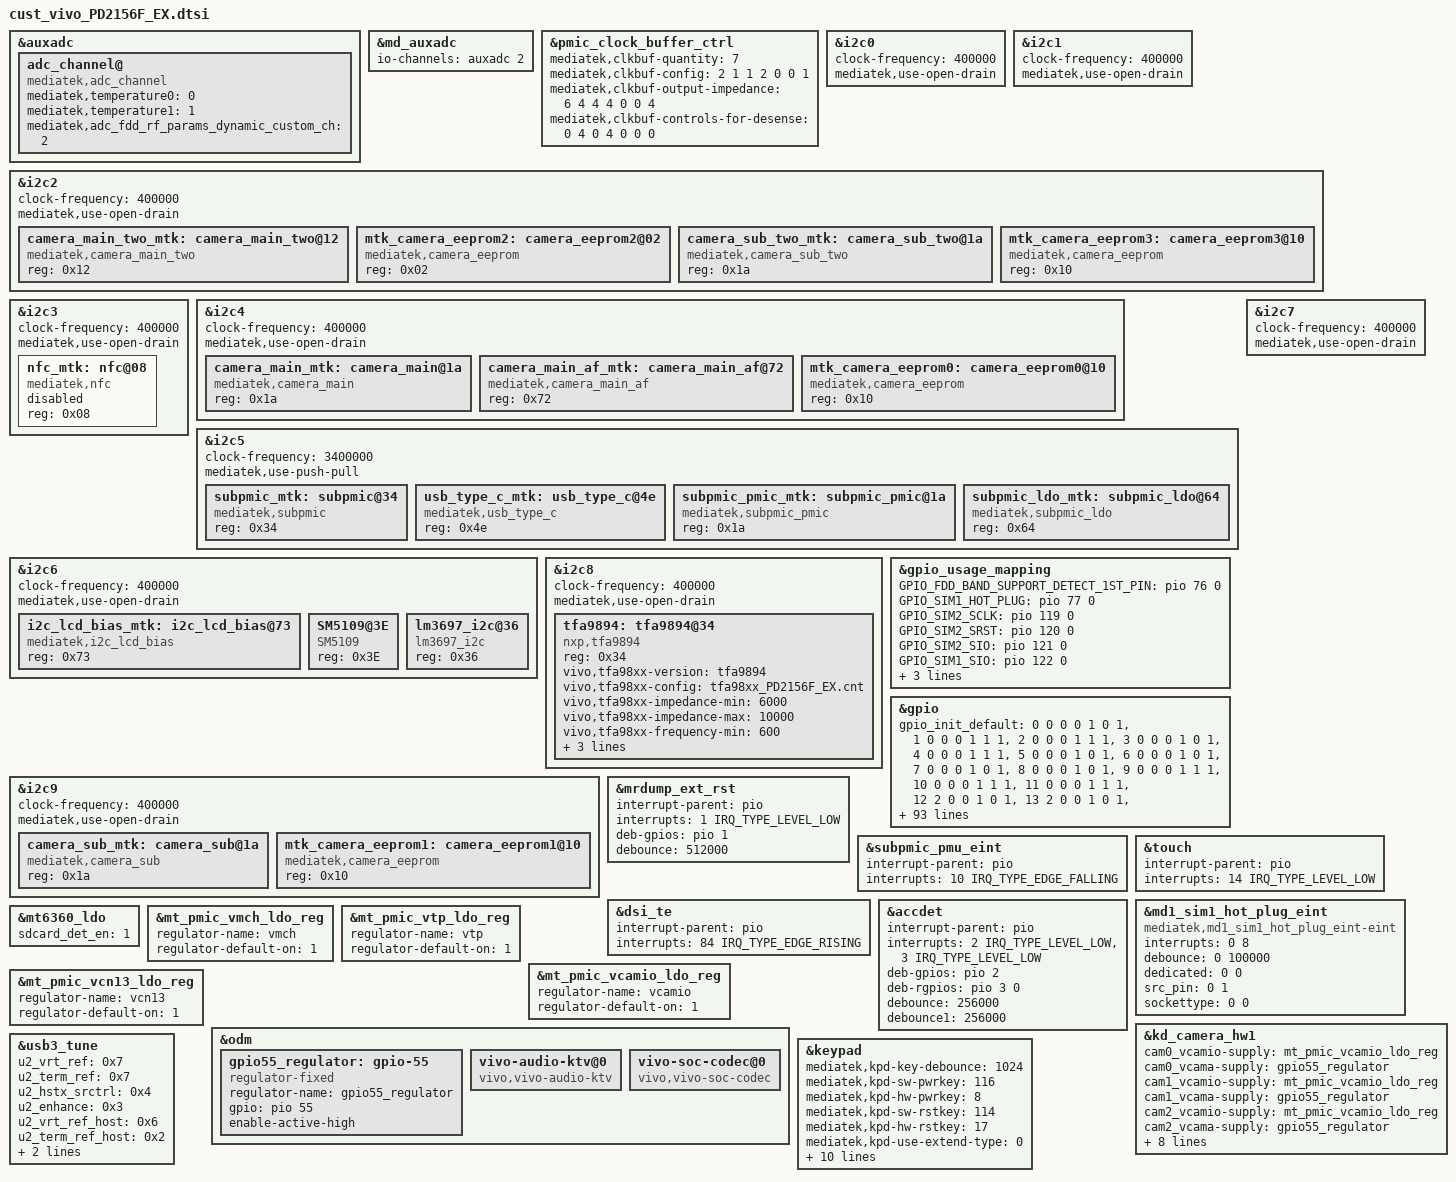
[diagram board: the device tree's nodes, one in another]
/*
 * Generated by MTK SP DrvGen Version: 3.5.160809 for MT6833.
 * 2020-10-09 21:09:16
 * Do Not Modify The File.
 * Copyright Mediatek Inc. (c) 2016.
*/

/*************************
 * ADC DTSI File
*************************/

&auxadc {
	adc_channel@ {
		compatible = "mediatek,adc_channel";
		mediatek,temperature0 = <0>;
		mediatek,temperature1 = <1>;
		mediatek,adc_fdd_rf_params_dynamic_custom_ch = <2>;
		status = "okay";
	};
};
&md_auxadc {
	io-channels = <&auxadc 2>;
};


/*************************
 * CLK_BUF DTSI File
*************************/

&pmic_clock_buffer_ctrl {
	mediatek,clkbuf-quantity = <7>;
	mediatek,clkbuf-config = <2 1 1 2 0 0 1>;
	mediatek,clkbuf-output-impedance = <6 4 4 4 0 0 4>;
	mediatek,clkbuf-controls-for-desense = <0 4 0 4 0 0 0>;
	status = "okay";
};


/*************************
 * I2C DTSI File
*************************/

&i2c0 {
	#address-cells = <1>;
	#size-cells = <0>;
	clock-frequency = <400000>;
	mediatek,use-open-drain;
};

&i2c1 {
	#address-cells = <1>;
	#size-cells = <0>;
	clock-frequency = <400000>;
	mediatek,use-open-drain;
};

&i2c2 {
	#address-cells = <1>;
	#size-cells = <0>;
	clock-frequency = <400000>;
	mediatek,use-open-drain;
	
	camera_main_two_mtk:camera_main_two@12 {
		compatible = "mediatek,camera_main_two";
		reg = <0x12>;
		status = "okay";
	};
	
	mtk_camera_eeprom2:camera_eeprom2@02 {
		compatible = "mediatek,camera_eeprom";
		reg = <0x02>;
		status = "okay";
	};

	camera_sub_two_mtk:camera_sub_two@1a {
		compatible = "mediatek,camera_sub_two";
		reg = <0x1a>;
		status = "okay";
	};
	mtk_camera_eeprom3:camera_eeprom3@10 {
		compatible = "mediatek,camera_eeprom";
		reg = <0x10>;
		status = "okay";
	};

};

&i2c3 {
	#address-cells = <1>;
	#size-cells = <0>;
	clock-frequency = <400000>;
	mediatek,use-open-drain;
	nfc_mtk:nfc@08 {
		compatible = "mediatek,nfc";
		reg = <0x08>;
		status = "disabled";
	};

};

&i2c4 {
	#address-cells = <1>;
	#size-cells = <0>;
	clock-frequency = <400000>;
	mediatek,use-open-drain;
	camera_main_mtk:camera_main@1a {
		compatible = "mediatek,camera_main";
		reg = <0x1a>;
		status = "okay";
	};
	camera_main_af_mtk:camera_main_af@72 {
		compatible = "mediatek,camera_main_af";
		reg = <0x72>;
		status = "okay";
	};

	mtk_camera_eeprom0:camera_eeprom0@10 {
		compatible = "mediatek,camera_eeprom";
		reg = <0x10>;
		status = "okay";
	};

};

&i2c5 {
	#address-cells = <1>;
	#size-cells = <0>;
	clock-frequency = <3400000>;
	mediatek,use-push-pull;
	subpmic_mtk:subpmic@34 {
		compatible = "mediatek,subpmic";
		reg = <0x34>;
		status = "okay";
	};

	usb_type_c_mtk:usb_type_c@4e {
		compatible = "mediatek,usb_type_c";
		reg = <0x4e>;
		status = "okay";
	};

	subpmic_pmic_mtk:subpmic_pmic@1a {
		compatible = "mediatek,subpmic_pmic";
		reg = <0x1a>;
		status = "okay";
	};

	subpmic_ldo_mtk:subpmic_ldo@64 {
		compatible = "mediatek,subpmic_ldo";
		reg = <0x64>;
		status = "okay";
	};

};

&i2c6 {
	#address-cells = <1>;
	#size-cells = <0>;
	clock-frequency = <400000>;
	mediatek,use-open-drain;
	i2c_lcd_bias_mtk:i2c_lcd_bias@73 {
		compatible = "mediatek,i2c_lcd_bias";
		reg = <0x73>;
		status = "okay";
	};
	SM5109@3E {
		compatible = "SM5109";
		reg = <0x3E>;
		status = "okay";
	};
	lm3697_i2c@36 {
		compatible = "lm3697_i2c";
		reg = <0x36>;
		status = "okay";
	};
};

&i2c7 {
	#address-cells = <1>;
	#size-cells = <0>;
	clock-frequency = <400000>;
	mediatek,use-open-drain;
};

&i2c8 {
	#address-cells = <1>;
	#size-cells = <0>;
	clock-frequency = <400000>;
	mediatek,use-open-drain;



};

&i2c9 {
	#address-cells = <1>;
	#size-cells = <0>;
	clock-frequency = <400000>;
	mediatek,use-open-drain;
	
	camera_sub_mtk:camera_sub@1a {
		compatible = "mediatek,camera_sub";
		reg = <0x1a>;
		status = "okay";
	};
	
	mtk_camera_eeprom1:camera_eeprom1@10 {
		compatible = "mediatek,camera_eeprom";
		reg = <0x10>;
		status = "okay";
	};


};



/*************************
 * GPIO DTSI File
*************************/

&gpio_usage_mapping {
	GPIO_FDD_BAND_SUPPORT_DETECT_1ST_PIN = <&pio 76 0>;
	GPIO_SIM1_HOT_PLUG = <&pio 77 0>;
	GPIO_SIM2_SCLK = <&pio 119 0>;
	GPIO_SIM2_SRST = <&pio 120 0>;
	GPIO_SIM2_SIO = <&pio 121 0>;
	GPIO_SIM1_SIO = <&pio 122 0>;
	GPIO_SIM1_SRST = <&pio 123 0>;
	GPIO_SIM1_SCLK = <&pio 124 0>;
	GPIO_RF_PWREN_RST_PIN = <&pio 170 0>;
};

&gpio{
	gpio_init_default = <0 0 0 0 1 0 1>,
		<1 0 0 0 1 1 1>,
		<2 0 0 0 1 1 1>,
		<3 0 0 0 1 0 1>,
		<4 0 0 0 1 1 1>,
		<5 0 0 0 1 0 1>,
		<6 0 0 0 1 0 1>,
		<7 0 0 0 1 0 1>,
		<8 0 0 0 1 0 1>,
		<9 0 0 0 1 1 1>,
		<10 0 0 0 1 1 1>,
		<11 0 0 0 1 1 1>,
		<12 2 0 0 1 0 1>,
		<13 2 0 0 1 0 1>,
		<14 0 0 0 1 1 1>,
		<15 0 0 0 0 0 0>,
		<16 0 0 0 1 1 0>,
		<17 0 1 0 0 0 1>,
		<18 7 0 0 1 0 1>,
		<19 0 0 0 0 0 1>,
		<20 7 0 0 1 0 1>,
		<21 0 0 0 0 0 1>,
		<22 0 0 0 0 0 1>,
		<23 7 0 0 1 0 1>,
		<24 7 0 0 1 0 1>,
		<25 0 0 0 1 1 0>,
		<26 7 0 0 1 0 1>,
		<27 1 1 0 0 0 1>,
		<28 1 1 0 0 0 1>,
		<29 1 1 0 0 0 1>,
		<30 1 0 0 0 0 1>,
		<31 2 0 0 0 0 1>,
		<32 2 0 0 0 0 1>,
		<33 2 0 0 0 0 1>,
		<34 2 0 0 1 0 1>,
		<35 0 1 0 0 0 1>,
		<36 0 1 0 0 0 1>,
		<37 1 0 0 1 0 1>,
		<38 1 0 0 1 0 1>,
		<39 0 0 0 1 1 1>,
		<40 1 0 0 0 0 1>,
		<41 1 0 0 0 0 1>,
		<42 1 0 0 1 0 1>,
		<43 1 0 0 0 0 1>,
		<44 0 1 0 1 1 1>,
		<45 0 1 1 0 0 0>,
		<46 0 0 0 1 0 1>,
		<47 0 0 0 0 0 1>,
		<48 0 0 0 1 0 1>,
		<49 1 1 0 0 0 0>, //cam0 clk0
		<50 1 1 0 0 0 0>, //cam2 clk1
		<51 1 1 0 0 0 0>, //cam3 clk2
		<52 1 1 0 0 0 0>, //cam1 clk3
		<53 0 1 0 1 0 1>,
		<54 0 1 0 0 0 0>, //cam0 rst0
		<55 0 1 0 0 0 0>, //cam0123 avdd
		<56 0 1 0 0 0 0>,
		<57 0 1 0 0 0 0>,
		<58 0 1 0 0 0 0>, //cam2 rst2
		<59 0 1 0 0 0 0>, //cam0 dvdd
		<60 0 1 0 0 0 0>, //cam1 rst3
		<61 1 0 0 1 1 1>,
		<62 1 0 0 0 0 1>,
		<63 1 0 0 1 1 1>,
		<64 1 0 0 0 0 1>,
		<65 0 0 0 1 1 0>,
		<66 0 0 0 1 1 0>,
		<67 0 1 0 1 1 0>,
		<69 0 0 0 1 1 0>,
		<70 0 0 0 1 1 0>,
		<72 0 1 0 1 0 1>,
		<73 0 0 0 1 1 0>,
		<74 0 1 0 1 0 1>,
		<75 0 0 0 1 1 0>,
		<76 0 0 0 1 1 0>,
		<77 1 0 0 1 1 1>,
		<78 0 0 0 0 0 1>,
		<79 1 0 0 1 1 1>,
		<80 0 1 0 1 0 1>,
		<81 3 0 0 1 0 1>,
		<82 0 1 0 1 0 1>,
		<83 1 0 0 0 0 1>,
		<84 1 0 0 1 0 1>,
		<85 1 0 0 0 0 1>,
		<86 0 1 0 0 0 0>,
		<87 2 0 0 1 0 1>,
		<88 0 0 0 1 0 1>,
		<89 0 0 0 1 0 1>,
		<90 1 0 0 0 0 1>,
		<91 0 0 0 1 1 0>,
		<92 0 1 0 1 0 1>,
		<93 0 1 0 1 0 1>,
		<94 0 1 0 1 0 1>,
		<95 1 0 0 1 0 1>,
		<96 1 0 0 1 0 1>,
		<97 2 0 0 1 1 1>,
		<98 2 0 0 1 1 1>,
		<99 2 0 0 1 1 1>,
		<100 2 0 0 1 1 1>,
		<101 1 0 0 1 1 1>, //i2c2 sda
		<102 1 0 0 1 1 1>, //i2c2 scl
		<103 1 0 0 1 1 1>,
		<104 1 0 0 1 1 1>, 
		<105 1 0 0 0 0 1>, //i2c4 sda
		<106 1 0 0 0 0 1>, //i2c4 scl
		<107 1 0 0 1 1 1>,
		<108 1 0 0 1 1 1>,
		<109 1 0 0 1 1 1>,
		<110 1 0 0 1 1 1>,
		<111 1 0 0 1 1 1>,
		<112 1 0 0 1 1 1>,
		<113 1 0 0 1 1 1>,
		<114 1 0 0 1 1 1>,
		<115 1 0 0 1 0 1>,
		<116 1 0 0 1 0 1>,
		<117 0 0 0 1 0 1>,
		<118 0 0 0 1 0 1>,
		<119 1 0 0 0 0 1>,
		<120 1 0 0 0 0 1>,
		<121 1 0 0 1 1 1>,
		<122 1 0 0 1 1 1>,
		<123 1 0 0 0 0 1>,
		<124 1 0 0 0 0 1>,
		<125 1 0 0 0 0 1>,
		<126 1 0 0 1 1 1>,
		<127 1 0 0 1 1 1>,
		<128 1 0 0 1 1 1>,
		<129 1 0 0 1 1 1>,
		<130 1 0 0 1 1 1>,
		<131 0 1 0 1 0 1>,
		<132 0 1 0 1 0 1>,
		<133 0 1 0 1 0 1>,
		<134 0 1 0 1 0 1>,
		<135 0 1 0 1 0 1>,
		<136 0 1 1 1 0 1>,
		<137 0 1 0 1 0 1>,
		<138 0 1 0 1 0 1>,
		<139 0 1 0 1 0 1>,
		<140 0 1 0 0 0 0>,
		<141 1 0 0 0 0 1>, //cam1 i2c9 sda
		<142 1 0 0 0 0 1>, //cam1 i2c9 scl
		<143 1 0 0 0 0 1>,
		<144 1 0 0 0 0 1>,
		<145 1 0 0 0 0 1>,
		<146 1 0 0 0 0 1>,
		<147 1 0 0 0 0 1>,
		<148 1 0 0 0 0 1>,
		<149 1 0 0 1 0 1>,
		<150 1 0 0 1 0 1>,
		<151 1 0 0 1 0 1>,
		<152 1 0 0 1 0 1>,
		<153 1 0 0 0 0 1>,
		<154 1 0 0 0 0 1>,
		<155 1 0 0 0 0 1>,
		<156 1 0 0 0 0 1>,
		<157 1 0 0 0 0 1>,
		<158 1 0 0 0 0 1>,
		<159 1 0 0 1 0 1>,
		<160 1 0 0 1 0 1>,
		<161 1 0 0 1 0 1>,
		<162 1 0 0 0 0 0>,
		<163 1 0 0 1 0 0>,
		<164 1 0 0 1 0 1>,
		<165 1 0 0 1 0 1>,
		<166 0 0 0 1 1 0>,
		<167 0 0 0 1 1 0>,
		<168 1 0 0 0 0 1>,
		<169 1 0 0 0 0 1>,
		<170 0 1 1 1 0 1>,
		<171 1 0 0 0 0 1>,
		<172 1 0 0 0 0 1>,
		<173 1 0 0 0 0 1>,
		<174 0 0 0 1 1 0>,
		<175 0 0 0 1 1 1>,
		<176 1 0 0 0 0 1>,
		<177 1 0 0 0 0 1>,
		<178 1 0 0 0 0 1>,
		<179 1 0 0 0 0 1>,
		<180 1 0 0 0 0 1>,
		<181 1 0 0 0 0 1>,
		<182 1 0 0 0 0 1>,
		<183 0 0 0 1 1 0>,
		<184 0 1 0 1 0 1>,
		<185 0 0 0 1 1 0>,
		<186 1 0 0 0 0 1>,
		<187 1 0 0 0 0 1>,
		<188 1 0 0 0 0 0>,
		<189 1 0 0 1 0 0>,
		<190 1 0 0 0 0 0>,
		<191 1 0 0 1 0 0>,
		<192 0 0 0 1 0 1>,
		<193 0 0 0 1 0 1>,
		<194 0 0 0 1 0 1>,
		<195 0 0 0 1 0 1>,
		<196 0 0 0 1 0 1>,
		<197 0 0 0 1 0 1>,
		<198 0 0 0 1 0 1>,
		<199 0 0 0 1 0 1>,
		<200 0 0 0 1 0 1>;
};


/*************************
 * EINT DTSI File
*************************/

#include <dt-bindings/interrupt-controller/irq.h>
#include <dt-bindings/interrupt-controller/arm-gic.h>

&mrdump_ext_rst {
	interrupt-parent = <&pio>;
	interrupts = <1 IRQ_TYPE_LEVEL_LOW>;
	deb-gpios = <&pio 1 0>;
	debounce = <512000>;
	status = "okay";
};

&subpmic_pmu_eint {
	interrupt-parent = <&pio>;
	interrupts = <10 IRQ_TYPE_EDGE_FALLING>;
	status = "okay";
};

&touch {
	interrupt-parent = <&pio>;
	interrupts = <14 IRQ_TYPE_LEVEL_LOW>;
	status = "okay";
};

&dsi_te {
	interrupt-parent = <&pio>;
	interrupts = <84 IRQ_TYPE_EDGE_RISING>;
	status = "okay";
};

&accdet {
	interrupt-parent = <&pio>;
	interrupts = <2 IRQ_TYPE_LEVEL_LOW>,
					<3 IRQ_TYPE_LEVEL_LOW>;
	deb-gpios = <&pio 2 0>;
	deb-rgpios = <&pio 3 0>;
	debounce = <256000>;
	debounce1 = <256000>;
	status = "okay";
};

/*************************
 * MD1_EINT DTSI File
*************************/

&md1_sim1_hot_plug_eint {
	compatible = "mediatek,md1_sim1_hot_plug_eint-eint";
	interrupts = <0 8>;
	debounce = <0 100000>;
	dedicated = <0 0>;
	src_pin = <0 1>;
	sockettype = <0 0>;
	status = "okay";
};



/*************************
 * PMIC DTSI File
*************************/
&mt6360_ldo {
	sdcard_det_en = <1>;
};

&mt_pmic_vmch_ldo_reg {
	regulator-name = "vmch";
	regulator-default-on = <1>; /* 0:skip, 1: off, 2:on */
	status = "okay";
};

&mt_pmic_vtp_ldo_reg {
	regulator-name = "vmch";
	regulator-default-on = <1>; /* 0:skip, 1: off, 2:on */
	status = "okay";
};

&mt_pmic_vcamio_ldo_reg {
	regulator-name = "vcamio";
	regulator-default-on = <1>; /* 0:skip, 1: off, 2:on */
	status = "okay";
};
&mt_pmic_vtp_ldo_reg {
	regulator-name = "vtp";
	regulator-default-on = <1>; /* 0:skip, 1: off, 2:on */
	status = "okay";
};

&mt_pmic_vcn13_ldo_reg{
	regulator-name = "vcn13";
	regulator-default-on = <1>; /* 0:skip, 1: off, 2:on */
	status = "okay";
};
&kd_camera_hw1 {
	cam0_vcamio-supply = <&mt_pmic_vcamio_ldo_reg>;/*6365*/
	cam0_vcama-supply = <&gpio55_regulator>;
	cam1_vcamio-supply = <&mt_pmic_vcamio_ldo_reg>;
	cam1_vcama-supply = <&gpio55_regulator>;
	cam2_vcamio-supply = <&mt_pmic_vcamio_ldo_reg>;
	cam2_vcama-supply = <&gpio55_regulator>;
	cam3_vcamio-supply = <&mt_pmic_vcamio_ldo_reg>;
	cam3_vcama-supply = <&gpio55_regulator>;
	cam1_vcamd-supply = <&mt_pmic_vcn13_ldo_reg>;/*6365*/
	
	cam0_vcamaf_def-supply = <&mt_pmic_vtp_ldo_reg>;

	cam0_enable_sensor = "s5kjn1sq03pd2156f_mipi_raw";
	cam1_enable_sensor = "s5k3p9sppd2156f_mipi_raw";
	cam2_enable_sensor = "gc02m1bpd2156f_mipi_mono";
	cam3_enable_sensor = "gc02m1pd2156f_mipi_raw";
	status = "okay";
};
&odm {
	gpio55_regulator:gpio-55 {
			compatible = "regulator-fixed";
			regulator-name = "gpio55_regulator";
			gpio = <&pio 55 0x0>;
			enable-active-high;
			status = "okay";
	};
};

&camera_main_af_mtk{
         //vcamaf-supply = <&mt_pmic_vtp_ldo_reg>;
         status = "okay";
};



/*************************
 * POWER DTSI File
*************************/



/*************************
 * KPD DTSI File
*************************/

&keypad {
	mediatek,kpd-key-debounce = <1024>;
	mediatek,kpd-sw-pwrkey = <116>;
	mediatek,kpd-hw-pwrkey = <8>;
	mediatek,kpd-sw-rstkey  = <114>;
	mediatek,kpd-hw-rstkey = <17>;
	mediatek,kpd-use-extend-type = <0>;
	/*HW Keycode [0~71] -> Linux Keycode*/
	mediatek,kpd-hw-map-num = <72>;
	mediatek,kpd-hw-init-map = <115 0 0 0 0 0 0 0 0 0 0 0 0 0 0 0 0 0 0 0 0 0 0 0 0 0 0 0 0 0 0 0 0 0 0 0 0 0 0 0 0 0 0 0 0 0 0 0 0 0 0 0 0 0 0 0 0 0 0 0 0 0 0 0 0 0 0 0 0 0 0 0 >;
	mediatek,kpd-pwrkey-eint-gpio = <0>;
	mediatek,kpd-pwkey-gpio-din  = <0>;
	mediatek,kpd-hw-dl-key0 = <17>;
	mediatek,kpd-hw-dl-key1 = <0>;
	mediatek,kpd-hw-dl-key2 = <8>;
	mediatek,kpd-hw-recovery-key = <17>;
	mediatek,kpd-hw-factory-key = <0>;
	status = "okay";
};

/* fengmingli add for usb start */
&usb3_tune {
	u2_vrt_ref = <0x7>;
	u2_term_ref = <0x7>;
	u2_hstx_srctrl = <0x4>;
	u2_enhance = <0x3>;
	u2_vrt_ref_host = <0x6>;
	u2_term_ref_host = <0x2>;
	u2_hstx_srctrl_host = <0x4>;
	u2_enhance_host = <0x3>;
};
/* fengmingli add for usb end */


&odm {
	vivo-audio-ktv@0 {
		compatible = "vivo,vivo-audio-ktv";
		status = "okay";
	};

	vivo-soc-codec@0 {
		compatible = "vivo,vivo-soc-codec";
		status = "okay";
	};

};

/* wangkairjptb add for audio smartpa */
&i2c8{
	tfa9894: tfa9894@34 {
		status = "okay";
		compatible = "nxp,tfa9894";
		#sound-dai-cells = <1>;
		reg = <0x34>;
		vivo,tfa98xx-version = "tfa9894";
		vivo,tfa98xx-config = "tfa98xx_PD2156F_EX.cnt";
		vivo,tfa98xx-impedance-min = <6000>;
		vivo,tfa98xx-impedance-max = <10000>;
		vivo,tfa98xx-frequency-min = <600>;
		vivo,tfa98xx-frequency-max = <900>;
		vivo,tfa98xx-Qt-min = <110>;
		reset-gpio = <&pio 139 0>;
	};
};
/* ================================ */
